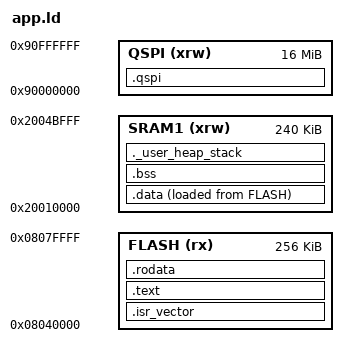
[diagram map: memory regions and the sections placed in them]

/* Entry Point */
ENTRY(Reset_Handler)

/* Highest address of the user mode stack */
_estack = ORIGIN(SRAM1) + LENGTH(SRAM1); /* end of "RAM" Ram type memory */

_Min_Heap_Size = 0x200; /* required amount of heap */
_Min_Stack_Size = 0x400; /* required amount of stack */

/* Memories definition */
MEMORY
{
  SRAM1    (xrw)    : ORIGIN = 0x20010000,   LENGTH = 240K
  FLASH    (rx)    : ORIGIN = 0x08040000,   LENGTH = 256K     /* SECTOR 5 */
  QSPI    (xrw)  : ORIGIN = 0x90000000, LENGTH = 16M
}

/* Sections */
SECTIONS
{
  /* The startup code into "FLASH" Rom type memory */
  .isr_vector :
  {
    . = ALIGN(4);
    KEEP(*(.isr_vector)) /* Startup code */
    . = ALIGN(4);
  } >FLASH

  /* The program code and other data into "FLASH" Rom type memory */
  .text :
  {
    . = ALIGN(4);
    *(.text)           /* .text sections (code) */
    *(.text*)          /* .text* sections (code) */
    *(.glue_7)         /* glue arm to thumb code */
    *(.glue_7t)        /* glue thumb to arm code */
    *(.eh_frame)

    KEEP (*(.init))
    KEEP (*(.fini))

    . = ALIGN(4);
    _etext = .;        /* define a global symbols at end of code */
  } >FLASH

  /* Constant data into "FLASH" Rom type memory */
  .rodata :
  {
    . = ALIGN(4);
    *(.rodata)         /* .rodata sections (constants, strings, etc.) */
    *(.rodata*)        /* .rodata* sections (constants, strings, etc.) */
    . = ALIGN(4);
  } >FLASH

  _qspi_init_base = LOADADDR(.qspi);
  _qspi_init_length = SIZEOF(.qspi);
  
  .qspi :
  {
    . = ALIGN(4);
    _qspi_start = .;        /* create a global symbol at qspi start */
    *(.qspi)         /* .qspi sections */
    *(.qspi*)        /* .qspi* sections */
    . = ALIGN(4);
    _qspi_end = .;         /* define a global symbols at end of qspi */
    
  } >QSPI

  /* Used by the startup to initialize data */
  _sidata = LOADADDR(.data);

  /* Initialized data sections into "RAM" Ram type memory */
  .data :
  {
    . = ALIGN(4);
    _sdata = .;        /* create a global symbol at data start */
    *(.data)           /* .data sections */
    *(.data*)          /* .data* sections */
    *(.RamFunc)        /* .RamFunc sections */
    *(.RamFunc*)       /* .RamFunc* sections */

    . = ALIGN(4);
    _edata = .;        /* define a global symbol at data end */

  } >SRAM1 AT> FLASH

  /* Uninitialized data section into "RAM" Ram type memory */
  . = ALIGN(4);
  .bss :
  {
    /* This is used by the startup in order to initialize the .bss section */
    _sbss = .;         /* define a global symbol at bss start */
    __bss_start__ = _sbss;
    *(.bss)
    *(.bss*)
    *(COMMON)

    . = ALIGN(4);
    _ebss = .;         /* define a global symbol at bss end */
    __bss_end__ = _ebss;
  } >SRAM1

  /* User_heap_stack section, used to check that there is enough "RAM" Ram  type memory left */
  ._user_heap_stack :
  {
    . = ALIGN(8);
    PROVIDE ( end = . );
    PROVIDE ( _end = . );
    . = . + _Min_Heap_Size;
    . = . + _Min_Stack_Size;
    . = ALIGN(8);
  } >SRAM1

  .ARM.attributes 0 : { *(.ARM.attributes) }
}

